# STM32H723 register map
File version: 1.6
CPU: CM7 r0p1, little endian, MPU, FPU, 4 interrupt priority bits
Registers are 32-bit, read-write, reset 0x0 unless marked. A register's access mark holds for its fields unless they carry their own. Offsets are from the block's base; [hi:lo] are bit positions; lines under a group give offsets from that group; {n}, {i} and the like mark numbered series.

## OctoSPII_O_Manager
Base 0x5200B400
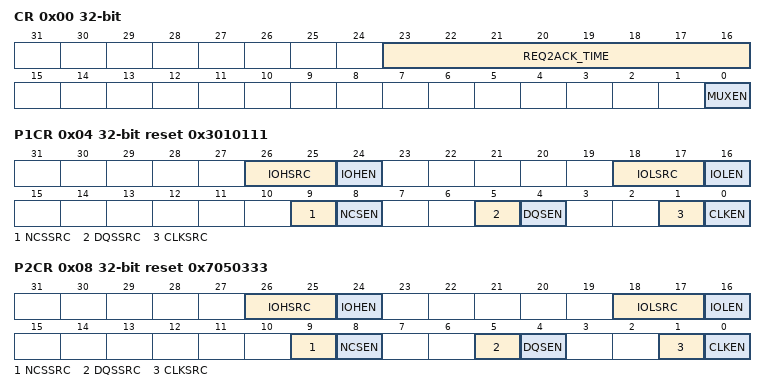
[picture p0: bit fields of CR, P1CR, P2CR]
0x00 CR — OctoSPI IO Manager Control Register
  [23:16] REQ2ACK_TIME — REQ to ACK Time
  [0] MUXEN — Multiplexed mode Enable
0x04 P1CR reset 0x3010111 — OctoSPI IO Manager Port 1 configuration register
  [26:25] IOHSRC
  [24] IOHEN
  [18:17] IOLSRC
  [16] IOLEN
  [9] NCSSRC
  [8] NCSEN
  [5] DQSSRC
  [4] DQSEN
  [1] CLKSRC — CLK/CLKn Source for Port n
  [0] CLKEN — CLK/CLKn Enable for Port n
0x08 P2CR reset 0x7050333 — OctoSPI IO Manager Port 2 configuration register
  [26:25] IOHSRC, [24] IOHEN, [18:17] IOLSRC, [16] IOLEN, [9] NCSSRC, [8] NCSEN, [5] DQSSRC, [4] DQSEN, [1] CLKSRC, [0] CLKEN

## RAMECC1 — ECC controller is associated to each RAM area
Base 0x52009000
Same registers: RAMECC2 0x48023000
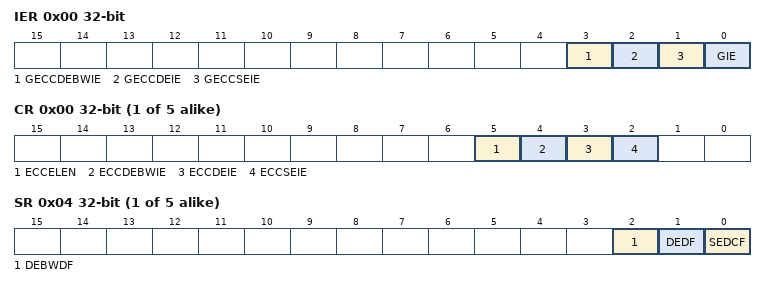
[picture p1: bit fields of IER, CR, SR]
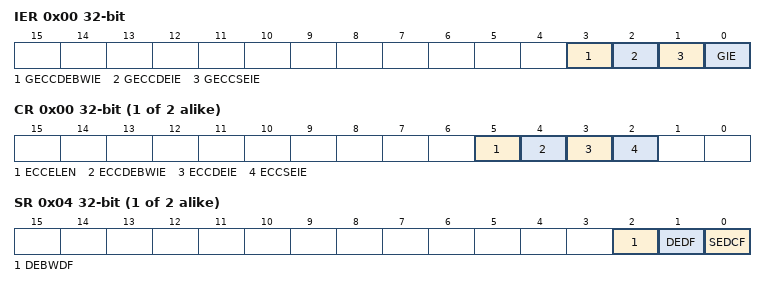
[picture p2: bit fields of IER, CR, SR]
0x00 IER — RAMECC interrupt enable register
  [3] GECCDEBWIE — Global ECC double error on byte write (BW) interrupt enable
  [2] GECCDEIE — Global ECC double error interrupt enable
  [1] GECCSEIE — Global ECC single error interrupt enable
  [0] GIE — Global interrupt enable
{0x0+0x20*i} M{i} (i=1..5) group — Cluster M{i}, containing M?CR, M?SR, M?FAR, M?FDRL, M?FDRH, M?FECR
  0x00 CR — RAMECC monitor x configuration register
    [5] ECCELEN — ECC error latching enable
    [4] ECCDEBWIE — ECC double error on byte write (BW) interrupt enable
    [3] ECCDEIE — ECC double error interrupt enable
    [2] ECCSEIE — ECC single error interrupt enable
  0x04 SR — RAMECC monitor x status register
    [2] DEBWDF — ECC double error on byte write (BW) detected flag
    [1] DEDF — ECC double error detected flag
    [0] SEDCF — ECC single error detected and corrected flag
  0x08 FAR ro — RAMECC monitor x failing address register
    [31:0] FADD — ECC error failing address
  0x0C FDRL ro — RAMECC monitor x failing data low register
    [31:0] FDATAL — Failing data low
  0x10 FDRH ro — RAMECC monitor x failing data high register
    [31:0] FDATAH — Failing data high (64-bit memory)
  0x14 FECR ro — RAMECC monitor x failing ECC error code register
    [31:0] FEC — Failing error code

## RAMECC3 — ECC controller is associated to each RAM area
Base 0x58027000
0x00 IER — RAMECC interrupt enable register
  [3] GECCDEBWIE — Global ECC double error on byte write (BW) interrupt enable
  [2] GECCDEIE — Global ECC double error interrupt enable
  [1] GECCSEIE — Global ECC single error interrupt enable
  [0] GIE — Global interrupt enable
{0x0+0x20*i} M{i} (i=1..2) group — Cluster M{i}, containing M?CR, M?SR, M?FAR, M?FDRL, M?FDRH, M?FECR
  0x00 CR — RAMECC monitor x configuration register
    [5] ECCELEN — ECC error latching enable
    [4] ECCDEBWIE — ECC double error on byte write (BW) interrupt enable
    [3] ECCDEIE — ECC double error interrupt enable
    [2] ECCSEIE — ECC single error interrupt enable
  0x04 SR — RAMECC monitor x status register
    [2] DEBWDF — ECC double error on byte write (BW) detected flag
    [1] DEDF — ECC double error detected flag
    [0] SEDCF — ECC single error detected and corrected flag
  0x08 FAR ro — RAMECC monitor x failing address register
    [31:0] FADD — ECC error failing address
  0x0C FDRL ro — RAMECC monitor x failing data low register
    [31:0] FDATAL — Failing data low
  0x10 FDRH ro — RAMECC monitor x failing data high register
    [31:0] FDATAH — Failing data high (64-bit memory)
  0x14 FECR ro — RAMECC monitor x failing ECC error code register
    [31:0] FEC — Failing error code

## SPDIFRX — Receiver Interface
Base 0x40004000
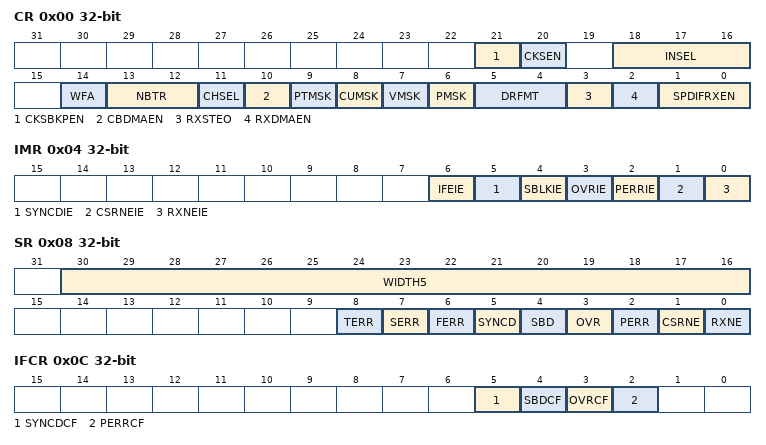
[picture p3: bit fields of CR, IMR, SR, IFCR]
0x00 CR — Control register
  [21] CKSBKPEN — Backup Symbol Clock Enable
  [20] CKSEN — Symbol Clock Enable
  [18:16] INSEL — input selection
  [14] WFA — Wait For Activity
  [13:12] NBTR — Maximum allowed re-tries during synchronization phase
  [11] CHSEL — Channel Selection
  [10] CBDMAEN — Control Buffer DMA ENable for control flow
  [9] PTMSK — Mask of Preamble Type bits
  [8] CUMSK — Mask of channel status and user bits
  [7] VMSK — Mask of Validity bit
  [6] PMSK — Mask Parity error bit
  [5:4] DRFMT — RX Data format
  [3] RXSTEO — STerEO Mode
  [2] RXDMAEN — Receiver DMA ENable for data flow
  [1:0] SPDIFRXEN — Peripheral Block Enable
0x04 IMR — Interrupt mask register
  [6] IFEIE — Serial Interface Error Interrupt Enable
  [5] SYNCDIE — Synchronization Done
  [4] SBLKIE — Synchronization Block Detected Interrupt Enable
  [3] OVRIE — Overrun error Interrupt Enable
  [2] PERRIE — Parity error interrupt enable
  [1] CSRNEIE — Control Buffer Ready Interrupt Enable
  [0] RXNEIE — RXNE interrupt enable
0x08 SR ro — Status register
  [30:16] WIDTH5 — Duration of 5 symbols counted with SPDIF_CLK
  [8] TERR — Time-out error
  [7] SERR — Synchronization error
  [6] FERR — Framing error
  [5] SYNCD — Synchronization Done
  [4] SBD — Synchronization Block Detected
  [3] OVR — Overrun error
  [2] PERR — Parity error
  [1] CSRNE — Control Buffer register is not empty
  [0] RXNE — Read data register not empty
0x0C IFCR wo — Interrupt Flag Clear register
  [5] SYNCDCF — Clears the Synchronization Done flag
  [4] SBDCF — Clears the Synchronization Block Detected flag
  [3] OVRCF — Clears the Overrun error flag
  [2] PERRCF — Clears the Parity error flag
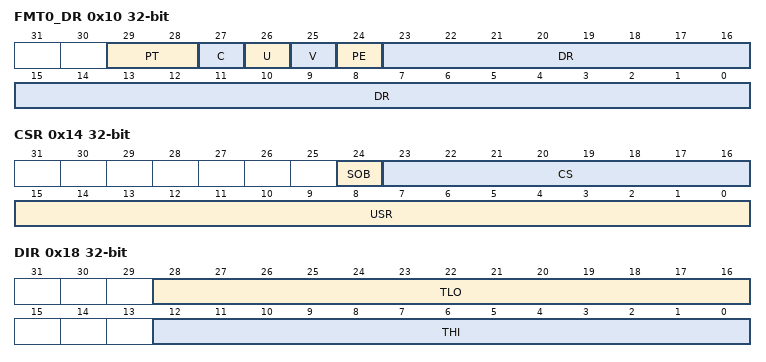
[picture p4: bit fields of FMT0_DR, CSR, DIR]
0x10 FMT0_DR ro — Data input register
  [29:28] PT — Preamble Type
  [27] C — Channel Status bit
  [26] U — User bit
  [25] V — Validity bit
  [24] PE — Parity Error bit
  [23:0] DR — Parity Error bit
0x14 CSR ro — Channel Status register
  [24] SOB — Start Of Block
  [23:16] CS — Channel A status information
  [15:0] USR — User data information
0x18 DIR ro — Debug Information register
  [28:16] TLO — Threshold LOW
  [12:0] THI — Threshold HIGH
